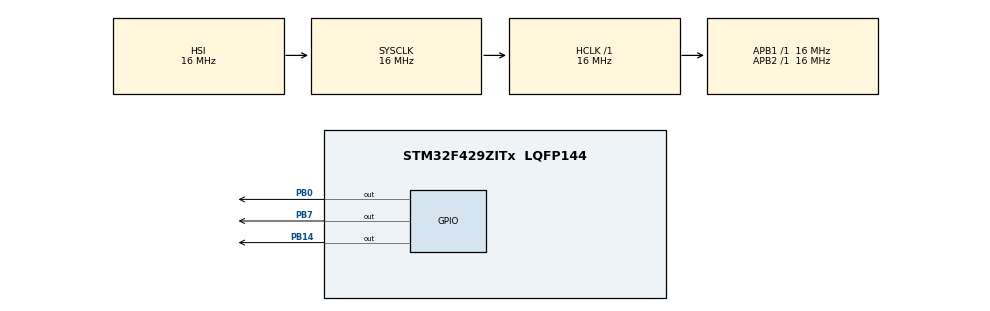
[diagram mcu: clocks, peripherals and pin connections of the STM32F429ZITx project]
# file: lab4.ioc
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FREERTOS.Tasks01=defaultTask,0,128,StartDefaultTask,Default,NULL,Dynamic,NULL,NULL;myTask02,-3,128,StartTask02,Default,NULL,Dynamic,NULL,NULL;myTask03,-3,128,StartTask03,Default,NULL,Dynamic,NULL,NULL;myTask04,-3,128,StartTask04,Default,NULL,Dynamic,NULL,NULL
Mcu.Family=STM32F4
Mcu.Name=STM32F429ZITx
Mcu.Package=LQFP144
NVIC.PriorityGroup=NVIC_PRIORITYGROUP_4
NVIC.TIM1_UP_TIM10_IRQn=true\:0\:0\:false\:false\:true\:false\:false\:true
NVIC.TimeBase=TIM1_UP_TIM10_IRQn
NVIC.TimeBaseIP=TIM1
PB0.Signal=GPIO_Output
PB14.Signal=GPIO_Output
PB7.Signal=GPIO_Output
PH0/OSC_IN.Mode=HSE-External-Oscillator
PH0/OSC_IN.Signal=RCC_OSC_IN
PH1/OSC_OUT.Mode=HSE-External-Oscillator
PH1/OSC_OUT.Signal=RCC_OSC_OUT
ProjectManager.HeapSize=0x200
ProjectManager.StackSize=0x400
ProjectManager.TargetToolchain=STM32CubeIDE
RCC.AHBFreq_Value=16000000
RCC.APB1Freq_Value=16000000
RCC.APB2Freq_Value=16000000
RCC.CortexFreq_Value=16000000
RCC.HSE_VALUE=25000000
RCC.HSI_VALUE=16000000
RCC.LSE_VALUE=32768
RCC.SYSCLKFreq_VALUE=16000000
RCC.VCOOutputFreq_Value=192000000
VP_FREERTOS_VS_CMSIS_V1.Mode=CMSIS_V1
VP_SYS_VS_tim1.Mode=TIM1
board=custom

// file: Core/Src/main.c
/* USER CODE BEGIN Header */
/**
  ******************************************************************************
  * @file           : main.c
  * @brief          : Main program body
  ******************************************************************************
  * @attention
  *
  * <h2><center>&copy; Copyright (c) 2020 STMicroelectronics.
  * All rights reserved.</center></h2>
  *
  * This software component is licensed by ST under BSD 3-Clause license,
  * the "License"; You may not use this file except in compliance with the
  * License. You may obtain a copy of the License at:
  *                        opensource.org/licenses/BSD-3-Clause
  *
  ******************************************************************************
  */
/* USER CODE END Header */

#include "main.h"
#include "cmsis_os.h"
#include "queue.h"
#include "semphr.h"

osThreadId defaultTaskHandle;
osThreadId myTask02Handle;
osThreadId myTask03Handle;
osThreadId myTask04Handle;

void SystemClock_Config(void);
static void MX_GPIO_Init(void);
void StartDefaultTask(void const * argument);
void StartTask02(void const * argument);
void StartTask03(void const * argument);
void StartTask04(void const * argument);
xQueueHandle q1;
xQueueHandle q2;
SemaphoreHandle_t xSemaphore;

int main(void)
{

  /* MCU Configuration--------------------------------------------------------*/

  /* Reset of all peripherals, Initializes the Flash interface and the Systick. */
  HAL_Init();

  /* Configure the system clock */
  SystemClock_Config();

  /* Initialize all configured peripherals */
  MX_GPIO_Init();

  /* USER CODE BEGIN RTOS_SEMAPHORES */
  /* add semaphores, ... */
  xSemaphore = xSemaphoreCreateMutex();
  /* USER CODE END RTOS_SEMAPHORES */

  /* USER CODE BEGIN RTOS_QUEUES */
  /* add queues, ... */
  q1 = xQueueCreate(4 , sizeof( int16_t ) );
  q2 = xQueueCreate(4 , sizeof( int16_t ) );
  /* USER CODE END RTOS_QUEUES */

  /* Create the thread(s) */
  /* definition and creation of defaultTask */
  osThreadDef(defaultTask, StartDefaultTask, osPriorityNormal, 0, 128);
  defaultTaskHandle = osThreadCreate(osThread(defaultTask), NULL);

  /* definition and creation of myTask02 */
  osThreadDef(myTask02, StartTask02, osPriorityIdle, 0, 128);
  myTask02Handle = osThreadCreate(osThread(myTask02), NULL);

  /* definition and creation of myTask03 */
  osThreadDef(myTask03, StartTask03, osPriorityIdle, 0, 128);
  myTask03Handle = osThreadCreate(osThread(myTask03), NULL);

  /* definition and creation of myTask04 */
  osThreadDef(myTask04, StartTask04, osPriorityIdle, 0, 128);
  myTask04Handle = osThreadCreate(osThread(myTask04), NULL);

  /* Start scheduler */
  osKernelStart();

  /* We should never get here as control is now taken by the scheduler */
  /* Infinite loop */
  while (1)
  {

  }
}

void SystemClock_Config(void)
{
  RCC_OscInitTypeDef RCC_OscInitStruct = {0};
  RCC_ClkInitTypeDef RCC_ClkInitStruct = {0};

  /** Configure the main internal regulator output voltage
  */
  __HAL_RCC_PWR_CLK_ENABLE();
  __HAL_PWR_VOLTAGESCALING_CONFIG(PWR_REGULATOR_VOLTAGE_SCALE3);
  /** Initializes the CPU, AHB and APB busses clocks
  */
  RCC_OscInitStruct.OscillatorType = RCC_OSCILLATORTYPE_HSI;
  RCC_OscInitStruct.HSIState = RCC_HSI_ON;
  RCC_OscInitStruct.HSICalibrationValue = RCC_HSICALIBRATION_DEFAULT;
  RCC_OscInitStruct.PLL.PLLState = RCC_PLL_NONE;
  if (HAL_RCC_OscConfig(&RCC_OscInitStruct) != HAL_OK)
  {
    Error_Handler();
  }
  /** Initializes the CPU, AHB and APB busses clocks
  */
  RCC_ClkInitStruct.ClockType = RCC_CLOCKTYPE_HCLK|RCC_CLOCKTYPE_SYSCLK
                              |RCC_CLOCKTYPE_PCLK1|RCC_CLOCKTYPE_PCLK2;
  RCC_ClkInitStruct.SYSCLKSource = RCC_SYSCLKSOURCE_HSI;
  RCC_ClkInitStruct.AHBCLKDivider = RCC_SYSCLK_DIV1;
  RCC_ClkInitStruct.APB1CLKDivider = RCC_HCLK_DIV1;
  RCC_ClkInitStruct.APB2CLKDivider = RCC_HCLK_DIV1;

  if (HAL_RCC_ClockConfig(&RCC_ClkInitStruct, FLASH_LATENCY_0) != HAL_OK)
  {
    Error_Handler();
  }
}

static void MX_GPIO_Init(void)
{
  GPIO_InitTypeDef GPIO_InitStruct = {0};

  /* GPIO Ports Clock Enable */
  __HAL_RCC_GPIOH_CLK_ENABLE();
  __HAL_RCC_GPIOB_CLK_ENABLE();

  /*Configure GPIO pin Output Level */
  HAL_GPIO_WritePin(GPIOB, GPIO_PIN_0|GPIO_PIN_14|GPIO_PIN_7, GPIO_PIN_RESET);

  /*Configure GPIO pins : PB0 PB14 PB7 */
  GPIO_InitStruct.Pin = GPIO_PIN_0|GPIO_PIN_14|GPIO_PIN_7;
  GPIO_InitStruct.Mode = GPIO_MODE_OUTPUT_PP;
  GPIO_InitStruct.Pull = GPIO_NOPULL;
  GPIO_InitStruct.Speed = GPIO_SPEED_FREQ_LOW;
  HAL_GPIO_Init(GPIOB, &GPIO_InitStruct);

}

void StartDefaultTask(void const * argument)
{
  for(;;)
  {
    osDelay(1);
  }
}

void StartTask02(void const * argument)
{
  /* USER CODE BEGIN StartTask02 */
  /* Infinite loop */
	int16_t SendNum=1;
  for(;;)
  {
	  xQueueSend(q1, ( void* )&SendNum, portMAX_DELAY);
	  xQueueSend(q2, ( void* )&SendNum, portMAX_DELAY);
	  SendNum++;
	  HAL_Delay(1000);
	  xQueueSend(q1, ( void* )&SendNum, portMAX_DELAY);
	  SendNum++;
	  HAL_Delay(1000);
//    osDelay(1);
  }
  /* USER CODE END StartTask02 */
}

void StartTask03(void const * argument)
{
  /* USER CODE BEGIN StartTask03 */
  /* Infinite loop */
  int16_t rec;
  for(;;)
  {
	  if ( xQueueReceive(q1,&(rec),portMAX_DELAY) == pdPASS)
	  {
		  xSemaphoreTake( xSemaphore, portMAX_DELAY );
		  while(rec>0)
		  {
			  HAL_GPIO_TogglePin(GPIOB, GPIO_PIN_7);
			  HAL_Delay(600);
			  rec--;
		  }
		  xSemaphoreGive( xSemaphore );
	  }
  }
  /* USER CODE END StartTask03 */
}

void StartTask04(void const * argument)
{
  /* USER CODE BEGIN StartTask04 */
  /* Infinite loop */
  int16_t rec;
  for(;;)
  {
	  if ( xQueueReceive(q2,&(rec),portMAX_DELAY) == pdPASS)
	  {
		  xSemaphoreTake( xSemaphore, portMAX_DELAY );
		  while(rec>0)
		  {
			  HAL_GPIO_TogglePin(GPIOB, GPIO_PIN_7);
			  HAL_Delay(600);
			  rec--;
		  }
		  xSemaphoreGive( xSemaphore );
	  }
  }
  /* USER CODE END StartTask04 */
}

 /**
  * @brief  Period elapsed callback in non blocking mode
  * @note   This function is called  when TIM1 interrupt took place, inside
  * HAL_TIM_IRQHandler(). It makes a direct call to HAL_IncTick() to increment
  * a global variable "uwTick" used as application time base.
  * @param  htim : TIM handle
  * @retval None
  */
void HAL_TIM_PeriodElapsedCallback(TIM_HandleTypeDef *htim)
{
  if (htim->Instance == TIM1) {
    HAL_IncTick();
  }
}

void Error_Handler(void)
{
}

/************************ (C) COPYRIGHT STMicroelectronics *****END OF FILE****/
